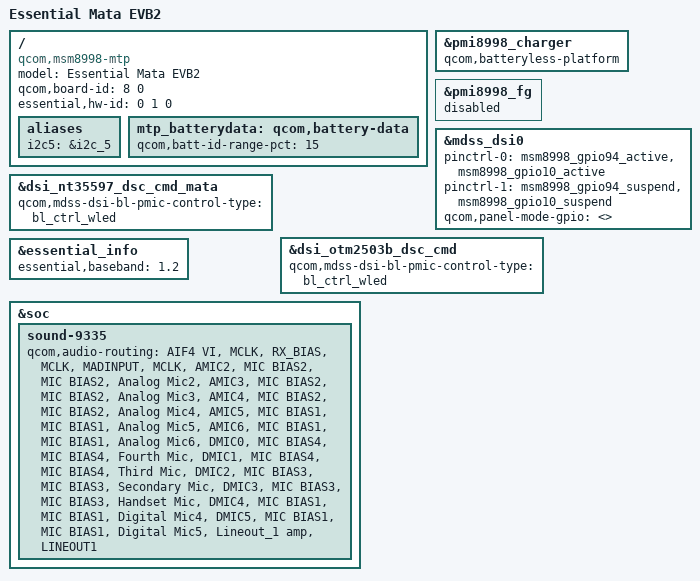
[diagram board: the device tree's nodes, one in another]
/* Copyright (c) 2016, The Linux Foundation. All rights reserved.
 *
 * This program is free software; you can redistribute it and/or modify
 * it under the terms of the GNU General Public License version 2 and
 * only version 2 as published by the Free Software Foundation.
 *
 * This program is distributed in the hope that it will be useful,
 * but WITHOUT ANY WARRANTY; without even the implied warranty of
 * MERCHANTABILITY or FITNESS FOR A PARTICULAR PURPOSE.  See the
 * GNU General Public License for more details.
 */


/dts-v1/;

#include "../qcom/msm8998-v2.1.dtsi"
#include "msm8998-mata.dtsi"

/ {
	model = "Essential Mata EVB2";
	compatible = "qcom,msm8998-mtp", "qcom,msm8998", "qcom,mtp";
	/* For now, we are using MTP ID */
	qcom,board-id = <8 0>;
	essential,hw-id = <0 1 0>;

	aliases {
		i2c5 = &i2c_5;
	};

	/delete-node/ qcom,battery-data;
	mtp_batterydata: qcom,battery-data {
		qcom,batt-id-range-pct = <15>;
		#include "battery-2080mah-evt0.dtsi"
	};
};

&pmi8998_charger {
	qcom,batteryless-platform;
};

&pmi8998_fg {
	status = "disabled";
};

&mdss_dsi0 {
	pinctrl-0 = <&msm8998_gpio94_active &msm8998_gpio10_active>;
	pinctrl-1 = <&msm8998_gpio94_suspend &msm8998_gpio10_suspend>;
	qcom,panel-mode-gpio = <>;
};

&dsi_nt35597_dsc_cmd_mata {
	qcom,mdss-dsi-bl-pmic-control-type = "bl_ctrl_wled";
};

&dsi_otm2503b_dsc_cmd {
	qcom,mdss-dsi-bl-pmic-control-type = "bl_ctrl_wled";
};

&essential_info {
	essential,baseband = "1.2";
};


&soc {
	sound-9335 {
		qcom,audio-routing =
			"AIF4 VI", "MCLK",
			"RX_BIAS", "MCLK",
			"MADINPUT", "MCLK",
			"AMIC2", "MIC BIAS2",
			"MIC BIAS2", "Analog Mic2",
			"AMIC3", "MIC BIAS2",
			"MIC BIAS2", "Analog Mic3",
			"AMIC4", "MIC BIAS2",
			"MIC BIAS2", "Analog Mic4",
			"AMIC5", "MIC BIAS1",
			"MIC BIAS1", "Analog Mic5",
			"AMIC6", "MIC BIAS1",
			"MIC BIAS1", "Analog Mic6",
			"DMIC0", "MIC BIAS4",
			"MIC BIAS4", "Fourth Mic",
			"DMIC1", "MIC BIAS4",
			"MIC BIAS4", "Third Mic",
			"DMIC2", "MIC BIAS3",
			"MIC BIAS3", "Secondary Mic",
			"DMIC3", "MIC BIAS3",
			"MIC BIAS3", "Handset Mic",
			"DMIC4", "MIC BIAS1",
			"MIC BIAS1", "Digital Mic4",
			"DMIC5", "MIC BIAS1",
			"MIC BIAS1", "Digital Mic5",
			"Lineout_1 amp", "LINEOUT1";
	};
};
